# COREDEBUG_356.0 register map
Vendor: Texas Instruments
Peripheral module from a debugger description file (folder MSP432).
Registers are 32-bit, read-write, no defined reset value unless marked. A register's access mark holds for its fields unless they carry their own. Offsets are as the file gives them; lines under a group give offsets from that group; [hi:lo] are bit positions; {n}, {i} and the like mark numbered series; 'fields as' and 'values as' point back to an identical list; <NAME> marks a mode.

## COREDEBUG
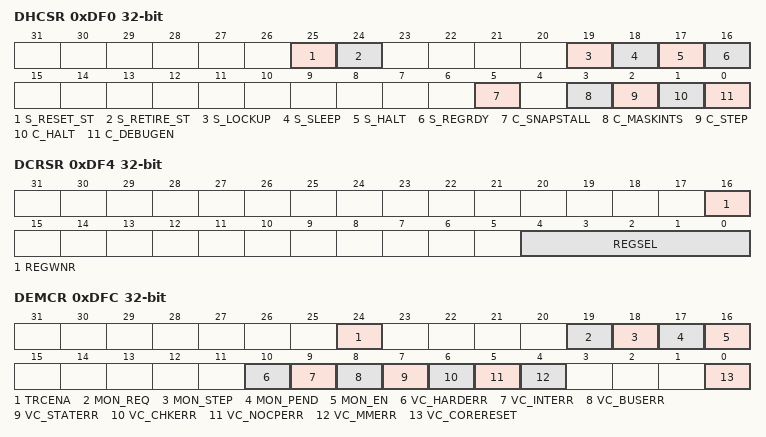
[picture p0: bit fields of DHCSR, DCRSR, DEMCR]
0xDF0 DHCSR access per field — Debug Halting Control and Status Register
  [25] S_RESET_ST ro — Indicates that the core has been reset, or is now being reset, since the last time this bit was read. This a sticky bit that clears on read. So, reading twice and getting 1 then 0 means it was reset in the past. Reading twice and getting 1 both times means that it is being reset now (held in reset still).
  [24] S_RETIRE_ST ro — Indicates that an instruction has completed since last read. This is a sticky bit that clears on read. This determines if the core is stalled on a load/store or fetch.
  [19] S_LOCKUP ro — Reads as one if the core is running (not halted) and a lockup condition is present.
  [18] S_SLEEP ro — Indicates that the core is sleeping (WFI, WFE, or SLEEP-ON-EXIT). Must use C_HALT to gain control or wait for interrupt to wake-up.
  [17] S_HALT ro — The core is in debug state when S_HALT is set.
  [16] S_REGRDY ro — Register Read/Write on the Debug Core Register Selector register is available. Last transfer is complete.
  [5] C_SNAPSTALL rw — If the core is stalled on a load/store operation the stall ceases and the instruction is forced to complete. This enables Halting debug to gain control of the core. It can only be set if: C_DEBUGEN = 1 and C_HALT = 1. The core reads S_RETIRE_ST as 0. This indicates that no instruction has advanced. This prevents misuse. The bus state is Unpredictable when this is used. S_RETIRE can detect core stalls on load/store operations.
  [3] C_MASKINTS rw — Mask interrupts when stepping or running in halted debug. Does not affect NMI, which is not maskable. Must only be modified when the processor is halted (S_HALT == 1). Also does not affect fault exceptions and SVC caused by execution of the instructions. CMASKINTS must be set or cleared before halt is released. This means that the writes to set or clear C_MASKINTS and to set or clear C_HALT must be separate.
  [2] C_STEP rw — Steps the core in halted debug. When C_DEBUGEN = 0, this bit has no effect. Must only be modified when the processor is halted (S_HALT == 1).
  [1] C_HALT rw — Halts the core. This bit is set automatically when the core Halts. For example Breakpoint. This bit clears on core reset. This bit can only be written if C_DEBUGEN is 1, otherwise it is ignored. When setting this bit to 1, C_DEBUGEN must also be written to 1 in the same value (value[1:0] is 2'b11). The core can halt itself, but only if C_DEBUGEN is already 1 and only if it writes with b11).
  [0] C_DEBUGEN rw — Enables debug. This can only be written by AHB-AP and not by the core. It is ignored when written by the core, which cannot set or clear it. The core must write a 1 to it when writing C_HALT to halt itself.
0xDF4 DCRSR — Deubg Core Register Selector Register
  [16] REGWNR — Write = 1, Read = 0
  [4:0] REGSEL — Register select
    0=en_0b00000 (R0); 1=en_0b00001 (R1); 2=en_0b00010 (R2); 3=en_0b00011 (R3); 4=en_0b00100 (R4); 5=en_0b00101 (R5); 6=en_0b00110 (R6); 7=en_0b00111 (R7); 8=en_0b01000 (R8); 9=en_0b01001 (R9); 10=en_0b01010 (R10); 11=en_0b01011 (R11); 12=en_0b01100 (R12); 13=en_0b01101 (Current SP); 14=en_0b01110 (LR); 15=en_0b01111 (DebugReturnAddress); 16=en_0b10000 (xPSR/flags, execution state information, and exception number); 17=en_0b10001 (MSP (Main SP)); 18=en_0b10010 (PSP (Process SP)); 20=en_0b10100 (CONTROL bits [31:24], FAULTMASK bits [23:16], BASEPRI bits [15:8], PRIMASK bits [7:0])
0xDF8 DCRDR access not given — Debug Core Register Data Register
0xDFC DEMCR — Debug Exception and Monitor Control Register
  [24] TRCENA — This bit must be set to 1 to enable use of the trace and debug blocks: Data Watchpoint and Trace (DWT), Instrumentation Trace Macrocell (ITM), Embedded Trace Macrocell (ETM), Trace Port Interface Unit (TPIU). This enables control of power usage unless tracing is required. The application can enable this, for ITM use, or use by a debugger. Note that if no debug or trace components are present in the implementation then it is not possible to set TRCENA.
  [19] MON_REQ — This enables the monitor to identify how it wakes up. This bit clears on a Core Reset.
    0=en_0b0 (woken up by debug exception.); 1=en_0b1 (woken up by MON_PEND)
  [18] MON_STEP — When MON_EN = 1, this steps the core. When MON_EN = 0, this bit is ignored. This is the equivalent to C_STEP. Interrupts are only stepped according to the priority of the monitor and settings of PRIMASK, FAULTMASK, or BASEPRI.
  [17] MON_PEND — Pend the monitor to activate when priority permits. This can wake up the monitor through the AHB-AP port. It is the equivalent to C_HALT for Monitor debug. This register does not reset on a system reset. It is only reset by a POR reset. Software in the reset handler or later, or by the DAP must enable the debug monitor.
  [16] MON_EN — Enable the debug monitor. When enabled, the System handler priority register controls its priority level. If disabled, then all debug events go to Hard fault. C_DEBUGEN in the Debug Halting Control and Statue register overrides this bit. Vector catching is semi-synchronous. When a matching event is seen, a Halt is requested. Because the processor can only halt on an instruction boundary, it must wait until the next instruction boundary. As a result, it stops on the first instruction of the exception handler. However, two special cases exist when a vector catch has triggered: 1. If a fault is taken during vectoring, vector read or stack push error, the halt occurs on the corresponding fault handler, for the vector error or stack push. 2. If a late arriving interrupt comes in during vectoring, it is not taken. That is, an implementation that supports the late arrival optimization must suppress it in this case.
  [10] VC_HARDERR — Debug trap on Hard Fault.
  [9] VC_INTERR — Debug Trap on interrupt/exception service errors. These are a subset of other faults and catches before BUSERR or HARDERR.
  [8] VC_BUSERR — Debug Trap on normal Bus error.
  [7] VC_STATERR — Debug trap on Usage Fault state errors.
  [6] VC_CHKERR — Debug trap on Usage Fault enabled checking errors.
  [5] VC_NOCPERR — Debug trap on Usage Fault access to Coprocessor that is not present or marked as not present in CAR register.
  [4] VC_MMERR — Debug trap on Memory Management faults.
  [0] VC_CORERESET — Reset Vector Catch. Halt running system if Core reset occurs.
